# MCXA156 register map
Vendor: nxp.com; File version: 1.0
CPU: CM33 r2p0, little endian, no MPU, FPU, VTOR, 3 interrupt priority bits
Registers are 32-bit, read-write, reset 0x0 unless marked. A register's access mark holds for its fields unless they carry their own. Offsets are from the block's base; [hi:lo] are bit positions; lines under a group give offsets from that group; {n}, {i} and the like mark numbered series; 'fields as' and 'values as' point back to an identical list.

## CAN0 — CAN
Base 0x400CC000
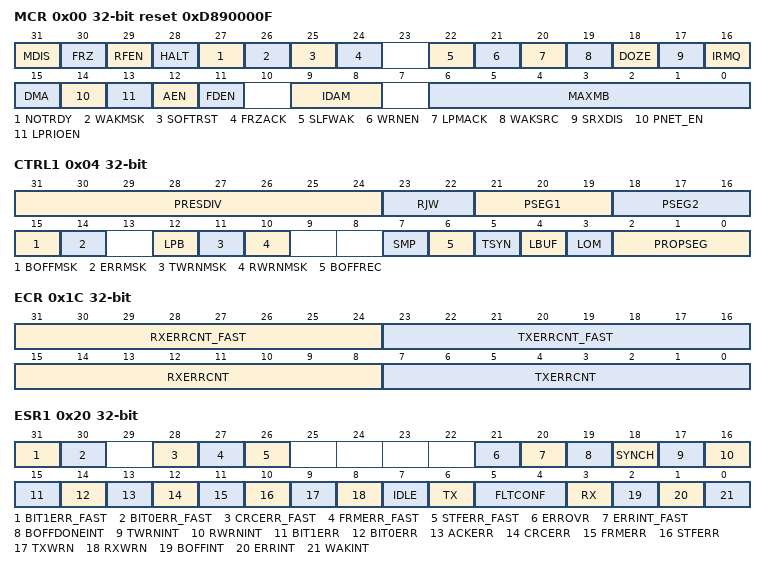
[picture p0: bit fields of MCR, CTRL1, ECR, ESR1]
0x00 MCR reset 0xD890000F — Module Configuration
  [31] MDIS — Module Disable
    0=flexcan_enabled (Enable); 1=flexcan_disabled (Disable)
  [30] FRZ — Freeze Enable
    0=freeze_mode_disabled (Disable); 1=freeze_mode_enabled (Enable)
  [29] RFEN — Legacy RX FIFO Enable
    0=id1 (Disable); 1=id2 (Enable)
  [28] HALT — Halt FlexCAN
    0=HALT_disable (No request); 1=HALT_enable (Enter Freeze mode, if MCR[FRZ] = 1.)
  [27] NOTRDY ro — FlexCAN Not Ready
    0=id1 (FlexCAN is in Normal mode, Listen-Only mode, or Loopback mode.); 1=id2 (FlexCAN is in Disable mode, Doze mode, Stop mode, or Freeze mode.)
  [26] WAKMSK — Wake-up Interrupt Mask
    0=wakeup_interrupt_disabled (Disabled); 1=wakeup_interrupt_enabled (Enabled)
  [25] SOFTRST — Soft Reset
    0=SOFTRST_no_reset_request (No reset); 1=SOFTRST_reset_registers (Soft reset affects reset registers)
  [24] FRZACK ro — Freeze Mode Acknowledge
    0=freeze_mode_no (Not in Freeze mode, prescaler running.); 1=freeze_mode_yes (In Freeze mode, prescaler stopped.)
  [22] SLFWAK — Self Wake-up
    0=self_wakeup_disabled (Disable); 1=self_wakeup_enabled (Enable)
  [21] WRNEN — Warning Interrupt Enable
    0=TWRNINT_RWRNINT_inactive (Disable); 1=TWRNINT_RWRNINT_active (Enable)
  [20] LPMACK ro — Low-Power Mode Acknowledge
    0=low_power_no (Not in a low-power mode); 1=low_power_yes (In a low-power mode)
  [19] WAKSRC — Wake-Up Source
    0=unfiltered_rx_input (No filter applied); 1=filtered_rx_input (Filter applied)
  [18] DOZE — Doze Mode Enable
    0=low_power_doze_disabled (Disable); 1=low_power_doze_enabled (Enable)
  [17] SRXDIS — Self-Reception Disable
    0=self_reception_enabled (Enable); 1=self_reception_disabled (Disable)
  [16] IRMQ — Individual RX Masking and Queue Enable
    0=individual_rx_masking_disabled (Disable); 1=individual_rx_masking_enabled (Enable)
  [15] DMA — DMA Enable
    0=id1 (Disable); 1=id2 (Enable)
  [14] PNET_EN — Pretended Networking Enable
    0=PN_disabled (Disable); 1=PN_enabled (Enable)
  [13] LPRIOEN — Local Priority Enable
    0=local_priority_disabled (Disable); 1=local_priority_enabled (Enable)
  [12] AEN — Abort Enable
    0=abort_disabled (Disabled); 1=abort_enabled (Enabled)
  [11] FDEN — CAN FD Operation Enable
    0=CAN_FD_disabled (Disable); 1=CAN_FD_enabled (Enable)
  [9:8] IDAM — ID Acceptance Mode
    0=one_full_ID (Format A: One full ID (standard and extended) per ID filter table element.); 1=two_full_ID (Format B: Two full standard IDs or two partial 14-bit (standard and extended) IDs per ID filter table element.); 2=four_partial_ID (Format C: Four partial 8-bit standard IDs per ID filter table element.); 3=all_frames_rejected (Format D: All frames rejected.)
  [6:0] MAXMB — Number of the Last Message Buffer
0x04 CTRL1 — Control 1
  [31:24] PRESDIV — Prescaler Division Factor
  [23:22] RJW — Resync Jump Width
  [21:19] PSEG1 — Phase Segment 1
  [18:16] PSEG2 — Phase Segment 2
  [15] BOFFMSK — Bus Off Interrupt Mask
    0=bus_off_int_disabled (Interrupt disabled); 1=bus_off_int_enabled (Interrupt enabled)
  [14] ERRMSK — Error Interrupt Mask
    0=error_int_disabled (Interrupt disabled); 1=error_int_enabled (Interrupt enabled)
  [12] LPB — Loopback Mode
    0=loopback_disabled (Disabled); 1=loopback_enabled (Enabled)
  [11] TWRNMSK — TX Warning Interrupt Mask
    0=tx_warning_int_disabled (Disabled); 1=tx_warning_int_enabled (Enabled)
  [10] RWRNMSK — RX Warning Interrupt Mask
    0=rx_warning_int_disabled (Disabled); 1=rx_warning_int_enabled (Enabled)
  [7] SMP — CAN Bit Sampling
    0=One sample is used to determine the bit value; 1=Three samples are used to determine the value of the received bit: the regular one (sample point) and two preceding samples. A majority rule is used.
  [6] BOFFREC — Bus Off Recovery
    0=auto_recover_enabled (Enabled); 1=auto_recover_disabled (Disabled)
  [5] TSYN — Timer Sync
    0=timer_sync_disabled (Disable); 1=timer_sync_enabled (Enable)
  [4] LBUF — Lowest Buffer Transmitted First
    0=highest_buffer_first (Buffer with highest priority is transmitted first.); 1=lowest_buffer_first (Lowest number buffer is transmitted first.)
  [3] LOM — Listen-Only Mode
    0=listen_only_mode_disabled (Listen-Only mode is deactivated.); 1=listen_only_mode_enabled (FlexCAN module operates in Listen-Only mode.)
  [2:0] PROPSEG — Propagation Segment
0x08 TIMER — Free-Running Timer
  [15:0] TIMER — Timer Value
0x10 RXMGMASK reset not defined — RX Message Buffers Global Mask
  [31:0] MG — Global Mask for RX Message Buffers
0x14 RX14MASK reset not defined — Receive 14 Mask
  [31:0] RX14M — RX Buffer 14 Mask Bits
0x18 RX15MASK reset not defined — Receive 15 Mask
  [31:0] RX15M — RX Buffer 15 Mask Bits
0x1C ECR — Error Counter
  [31:24] RXERRCNT_FAST — Receive Error Counter for Fast Bits
  [23:16] TXERRCNT_FAST — Transmit Error Counter for Fast Bits
  [15:8] RXERRCNT — Receive Error Counter
  [7:0] TXERRCNT — Transmit Error Counter
0x20 ESR1 — Error and Status 1
  [31] BIT1ERR_FAST ro — Fast Bit1 Error Flag
    0=bit1_error_no (No such occurrence.); 1=bit1_error_yes (At least one bit transmitted as recessive is received as dominant.)
  [30] BIT0ERR_FAST ro — Fast Bit0 Error Flag
    0=bit0_error_no (No such occurrence.); 1=bit0_error_yes (At least one bit transmitted as dominant is received as recessive.)
  [28] CRCERR_FAST ro — Fast Cyclic Redundancy Check Error Flag
    0=CRC_error_no (No such occurrence.); 1=CRC_error_yes (A CRC error occurred since last read of this register.)
  [27] FRMERR_FAST ro — Fast Form Error Flag
    0=form_error_no (No such occurrence.); 1=form_error_yes (A form error occurred since last read of this register.)
  [26] STFERR_FAST ro — Fast Stuffing Error Flag
    0=stuffing_error_no (No such occurrence.); 1=stuffing_error_yes (A stuffing error occurred since last read of this register.)
  [21] ERROVR write-1-clears — Error Overrun Flag
    0=overrun_not_occurred (No overrun); 1=overrun_occurred
  [20] ERRINT_FAST write-1-clears — Fast Error Interrupt Flag
    0=errors_data_phase_no (No such occurrence.); 1=errors_data_phase_yes (Error flag set in the data phase of CAN FD frames that have BRS = 1.)
  [19] BOFFDONEINT write-1-clears — Bus Off Done Interrupt Flag
    0=bus_off_not_done (No such occurrence); 1=bus_off_done (FlexCAN module has completed Bus Off process.)
  [18] SYNCH ro — CAN Synchronization Status Flag
    0=CAN_bus_sync_no (Not synchronized); 1=CAN_bus_sync_yes (Synchronized)
  [17] TWRNINT write-1-clears — TX Warning Interrupt Flag
    0=Tx_warning_int_no (No such occurrence); 1=Tx_warning_int_yes (TX error counter changed from less than 96 to greater than or equal to 96.)
  [16] RWRNINT write-1-clears — RX Warning Interrupt Flag
    0=Rx_warning_int_no (No such occurrence); 1=Rx_warning_int_yes (RX error counter changed from less than 96 to greater than or equal to 96.)
  [15] BIT1ERR ro — Bit1 Error Flag
    0=bit1_error_no (No such occurrence.); 1=bit1_error_yes (At least one bit sent as recessive is received as dominant.)
  [14] BIT0ERR ro — Bit0 Error Flag
    0=bit0_error_no (No such occurrence.); 1=bit0_error_yes (At least one bit sent as dominant is received as recessive.)
  [13] ACKERR ro — Acknowledge Error Flag
    0=ACK_error_no (No error); 1=ACK_error_yes (Error occurred since last read of this register.)
  [12] CRCERR ro — Cyclic Redundancy Check Error Flag
    0=CRC_error_no (No error); 1=CRC_error_yes (Error occurred since last read of this register.)
  [11] FRMERR ro — Form Error Flag
    0=form_error_no (No error); 1=form_error_yes (Error occurred since last read of this register.)
  [10] STFERR ro — Stuffing Error Flag
    0=stuffing_error_no (No error); 1=stuffing_error_yes (Error occurred since last read of this register.)
  [9] TXWRN ro — TX Error Warning Flag
    0=TXERRCNT_LT_96 (No such occurrence.); 1=TXERRCNT_GTE_96 (TXERRCNT is 96 or greater.)
  [8] RXWRN ro — RX Error Warning Flag
    0=RXERRCNT_LT_96 (No such occurrence.); 1=RXERRCNT_GTE_96 (RXERRCNT is greater than or equal to 96.)
  [7] IDLE ro
    0=can_bus_not_idle (Not IDLE); 1=can_bus_idle (IDLE)
  [6] TX ro — FlexCAN In Transmission
    0=transmit_message_no (Not transmitting); 1=transmit_message_yes (Transmitting)
  [5:4] FLTCONF ro — Fault Confinement State
    0=error_active; 1=error_passive; 0b1x=bus_off
  [3] RX ro — FlexCAN in Reception Flag
    0=DISABLE (Not receiving); 1=ENABLE (Receiving)
  [2] BOFFINT write-1-clears — Bus Off Interrupt Flag
    0=DISABLE (No such occurrence.); 1=ENABLE (FlexCAN module entered Bus Off state.)
  [1] ERRINT write-1-clears — Error Interrupt Flag
    0=DISABLE (No such occurrence.); 1=ENABLE (Indicates setting of any error flag in the Error and Status register.)
  [0] WAKINT write-1-clears — Wake-up Interrupt Flag
    0=DISABLE (No such occurrence.); 1=ENABLE (Indicates that a recessive-to-dominant transition was received on the CAN bus.)
0x28 IMASK1 — Interrupt Masks 1
  [31:0] BUF31TO0M — Buffer MBi Mask
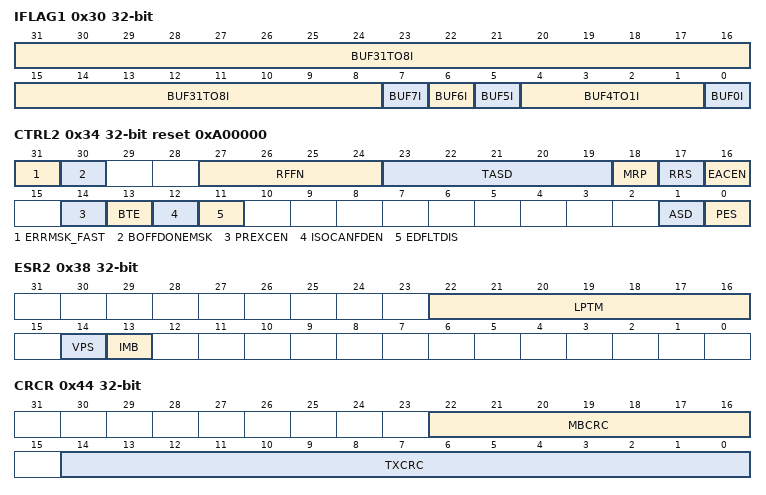
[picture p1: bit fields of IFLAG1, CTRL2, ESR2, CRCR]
0x30 IFLAG1 write-1-clears — Interrupt Flags 1
  [31:8] BUF31TO8I write-1-clears — Buffer MBi Interrupt
  [7] BUF7I write-1-clears — Buffer MB7 Interrupt or Legacy RX FIFO Overflow
    0=id1 (No occurrence of MB7 completing transmission or reception, or no FIFO overflow.); 1=id2 (MB7 completed transmission or reception, or FIFO overflow.)
  [6] BUF6I write-1-clears — Buffer MB6 Interrupt or Legacy RX FIFO Warning
    0=id1 (No occurrence of MB6 completing transmission or reception, or FIFO not almost full.); 1=id2 (MB6 completed transmission or reception, or FIFO almost full.)
  [5] BUF5I write-1-clears — Buffer MB5 Interrupt or Frames available in Legacy RX FIFO
    0=id1 (No occurrence of completed transmission or reception, or no frames available); 1=id2 (MB5 completed transmission or reception, or frames available)
  [4:1] BUF4TO1I write-1-clears — Buffer MBi Interrupt or Reserved
  [0] BUF0I write-1-clears — Buffer MB0 Interrupt or Clear Legacy FIFO bit
    0=buffer_Tx_Rx_not_complete (MB0 has no occurrence of successfully completed transmission or reception.); 1=buffer_Tx_Rx_complete (MB0 has successfully completed transmission or reception.)
0x34 CTRL2 reset 0xA00000 — Control 2
  [31] ERRMSK_FAST — Error Interrupt Mask for Errors Detected in the Data Phase of Fast CAN FD Frames
    0=DISABLE; 1=ENABLE
  [30] BOFFDONEMSK — Bus Off Done Interrupt Mask
    0=DISABLE; 1=ENABLE
  [27:24] RFFN — Number of Legacy Receive FIFO Filters
  [23:19] TASD — Transmission Arbitration Start Delay
  [18] MRP — Message Buffers Reception Priority
    0=id1 (Matching starts from Legacy RX FIFO or Enhanced RX FIFO and continues on message buffers.); 1=id3 (Matching starts from message buffers and continues on Legacy RX FIFO or Enhanced RX FIFO.)
  [17] RRS — Remote Request Storing
    0=remote_response_frame_not_generated (Generated); 1=remote_response_frame_generated (Stored)
  [16] EACEN — Entire Frame Arbitration Field Comparison Enable for RX Message Buffers
    0=RTR_compare_no (Disable); 1=RTR_compare_yes (Enable)
  [14] PREXCEN — Protocol Exception Enable
    0=DISABLE (Disabled); 1=ENABLE (Enabled)
  [13] BTE — Bit Timing Expansion Enable
    0=DISABLE; 1=ENABLE
  [12] ISOCANFDEN — ISO CAN FD Enable
    0=non_ISO (Disable); 1=ISO (Enable)
  [11] EDFLTDIS — Edge Filter Disable
    0=ENABLE (Enabled); 1=DISABLE (Disabled)
  [1] ASD — ACK Suppression Disable
    0=ENABLE (Enabled); 1=DISABLE (Disabled)
  [0] PES — Payload Byte and Bit Order Selection
    0=Big-endian; 1=Little-endian
0x38 ESR2 ro — Error and Status 2
  [22:16] LPTM — Lowest Priority TX Message Buffer
  [14] VPS — Valid Priority Status
    0=invalid; 1=valid
  [13] IMB — Inactive Message Buffer
    0=inactive_mailbox_no (Message buffer indicated by ESR2[LPTM] is not inactive.); 1=inactive_mailbox_yes (At least one message buffer is inactive.)
0x44 CRCR ro — Cyclic Redundancy Check
  [22:16] MBCRC — CRC Message Buffer
  [14:0] TXCRC — Transmitted CRC value
0x48 RXFGMASK reset not defined — Legacy RX FIFO Global Mask
  [31:0] FGM — Legacy RX FIFO Global Mask Bits
0x4C RXFIR ro reset not defined — Legacy RX FIFO Information
  [8:0] IDHIT — Identifier Acceptance Filter Hit Indicator
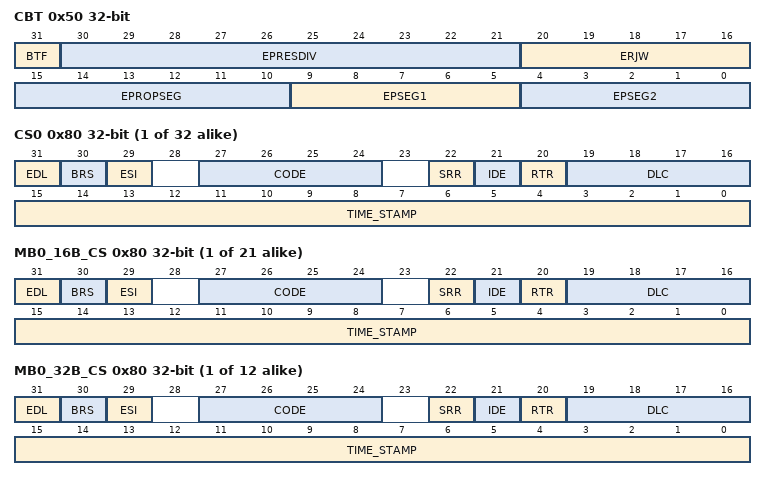
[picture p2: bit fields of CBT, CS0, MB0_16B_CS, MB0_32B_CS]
0x50 CBT — CAN Bit Timing
  [31] BTF — Bit Timing Format Enable
    0=DISABLE; 1=ENABLE
  [30:21] EPRESDIV — Extended Prescaler Division Factor
  [20:16] ERJW — Extended Resync Jump Width
  [15:10] EPROPSEG — Extended Propagation Segment
  [9:5] EPSEG1 — Extended Phase Segment 1
  [4:0] EPSEG2 — Extended Phase Segment 2
{0x80+0x10*i} CS{i} (MB_SIZE view) (i=0..31) — Message Buffer {i} CS Register
  [31] EDL — Extended Data Length. This bit distinguishes between CAN format and CAN FD format frames. The EDL bit must not be set for Message Buffers configured to RANSWER with code field 0b1010.
  [30] BRS — Bit Rate Switch. This bit defines whether the bit rate is switched inside a CAN FD format frame.
  [29] ESI — Error State Indicator. This bit indicates if the transmitting node is error active or error passive.
  [27:24] CODE — Message Buffer Code. This 4-bit field can be accessed (read or write) by the CPU and by the FlexCAN module itself, as part of the message buffer matching and arbitration process.
  [22] SRR — Substitute Remote Request. Contains a fixed recessive bit.
  [21] IDE — ID Extended. One/zero for extended/standard format frame.
  [20] RTR — Remote Transmission Request. One/zero for remote/data frame.
  [19:16] DLC — Length of the data to be stored/transmitted.
  [15:0] TIME_STAMP — Free-Running Counter Time stamp. This 16-bit field is a copy of the Free-Running Timer, captured for Tx and Rx frames at the time when the beginning of the Identifier field appears on the CAN bus.
{0x80+0x18*i} MB{i}_16B_CS (MB_SIZE view) (i=0..20) — Message Buffer {i} CS Register
  fields as CS0
{0x80+0x28*i} MB{i}_32B_CS (MB_SIZE view) (i=0..11) — Message Buffer {i} CS Register
  fields as CS0
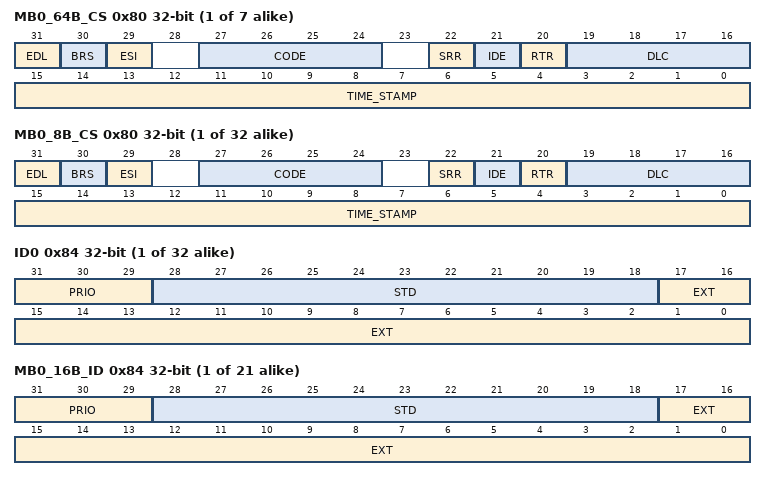
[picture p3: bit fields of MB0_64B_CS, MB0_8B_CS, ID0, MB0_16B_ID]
{0x80+0x48*i} MB{i}_64B_CS (MB_SIZE view) (i=0..6) — Message Buffer {i} CS Register
  fields as CS0
{0x80+0x10*i} MB{i}_8B_CS (MB_SIZE view) (i=0..31) — Message Buffer {i} CS Register
  fields as CS0
{0x84+0x10*i} ID{i} (MB_SIZE view) (i=0..31) — Message Buffer {i} ID Register
  [31:29] PRIO — Local priority. This 3-bit fieldis only used when LPRIO_EN bit is set in MCR and it only makes sense for Tx buffers. These bits are not transmitted. They are appended to the regular ID to define the transmission priority.
  [28:18] STD — Contains standard/extended (HIGH word) identifier of message buffer.
  [17:0] EXT — Contains extended (LOW word) identifier of message buffer.
{0x84+0x18*i} MB{i}_16B_ID (MB_SIZE view) (i=0..20) — Message Buffer {i} ID Register
  fields as ID0
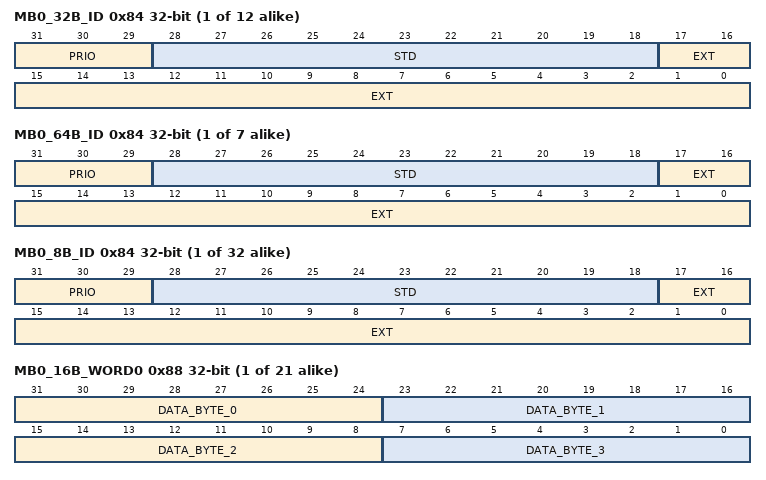
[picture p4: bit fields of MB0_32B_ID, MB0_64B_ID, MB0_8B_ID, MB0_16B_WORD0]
{0x84+0x28*i} MB{i}_32B_ID (MB_SIZE view) (i=0..11) — Message Buffer {i} ID Register
  fields as ID0
{0x84+0x48*i} MB{i}_64B_ID (MB_SIZE view) (i=0..6) — Message Buffer {i} ID Register
  fields as ID0
{0x84+0x10*i} MB{i}_8B_ID (MB_SIZE view) (i=0..31) — Message Buffer {i} ID Register
  fields as ID0
{0x88+0x18*i} MB{i}_16B_WORD0 (MB_SIZE view) (i=0..20) — Message Buffer {i} WORD_16B Register
  [31:24] DATA_BYTE_0 — Data byte 3 of Rx/Tx frame.
  [23:16] DATA_BYTE_1 — Data byte 2 of Rx/Tx frame.
  [15:8] DATA_BYTE_2 — Data byte 1 of Rx/Tx frame.
  [7:0] DATA_BYTE_3 — Data byte 0 of Rx/Tx frame.
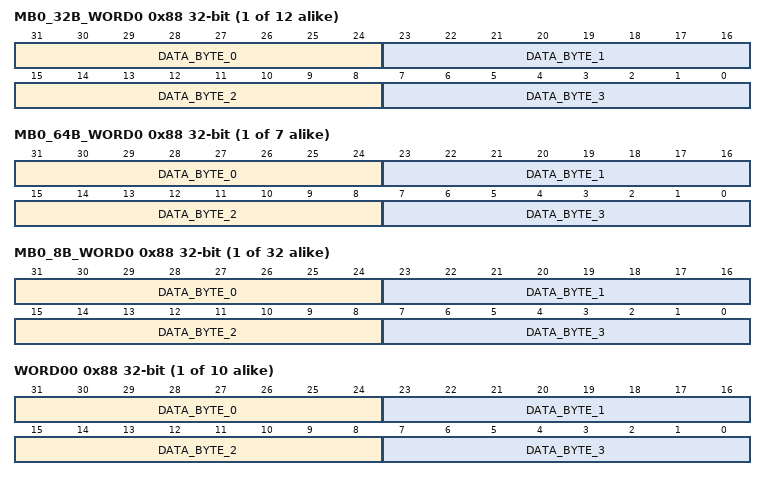
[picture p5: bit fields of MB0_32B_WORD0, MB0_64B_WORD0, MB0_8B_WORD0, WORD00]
{0x88+0x28*i} MB{i}_32B_WORD0 (MB_SIZE view) (i=0..11) — Message Buffer {i} WORD_32B Register
  fields as MB0_16B_WORD0
{0x88+0x48*i} MB{i}_64B_WORD0 (MB_SIZE view) (i=0..6) — Message Buffer {i} WORD_64B Register
  fields as MB0_16B_WORD0
{0x88+0x10*i} MB{i}_8B_WORD0 (MB_SIZE view) (i=0..31) — Message Buffer {i} WORD_8B Register
  fields as MB0_16B_WORD0
{0x88+0x10*i} WORD{i:02} (MB_SIZE view) (i=0..9) — Message Buffer {i} WORD0 Register
  fields as MB0_16B_WORD0
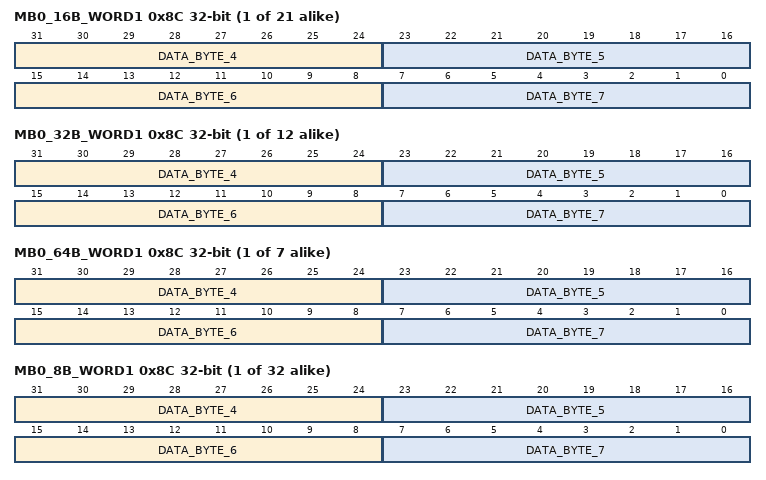
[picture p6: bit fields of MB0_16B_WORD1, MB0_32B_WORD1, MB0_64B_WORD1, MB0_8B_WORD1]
{0x8C+0x18*i} MB{i}_16B_WORD1 (MB_SIZE view) (i=0..20) — Message Buffer {i} WORD_16B Register
  [31:24] DATA_BYTE_4 — Data byte 3 of Rx/Tx frame.
  [23:16] DATA_BYTE_5 — Data byte 2 of Rx/Tx frame.
  [15:8] DATA_BYTE_6 — Data byte 1 of Rx/Tx frame.
  [7:0] DATA_BYTE_7 — Data byte 0 of Rx/Tx frame.
{0x8C+0x28*i} MB{i}_32B_WORD1 (MB_SIZE view) (i=0..11) — Message Buffer {i} WORD_32B Register
  fields as MB0_16B_WORD1
{0x8C+0x48*i} MB{i}_64B_WORD1 (MB_SIZE view) (i=0..6) — Message Buffer {i} WORD_64B Register
  fields as MB0_16B_WORD1
{0x8C+0x10*i} MB{i}_8B_WORD1 (MB_SIZE view) (i=0..31) — Message Buffer {i} WORD_8B Register
  fields as MB0_16B_WORD1
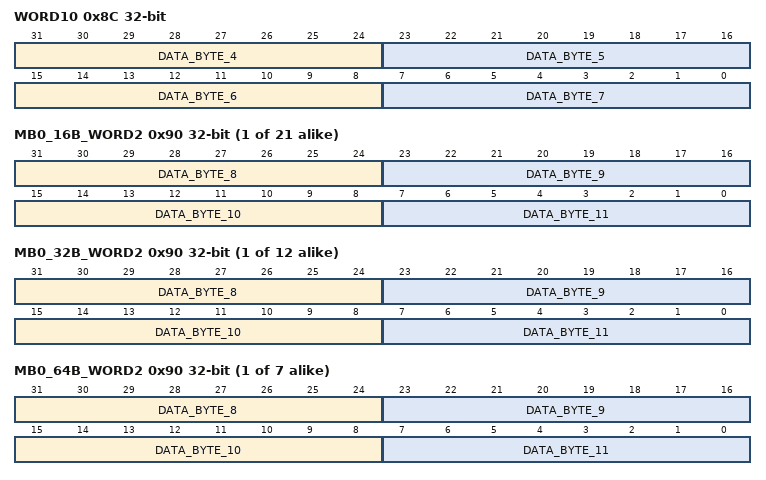
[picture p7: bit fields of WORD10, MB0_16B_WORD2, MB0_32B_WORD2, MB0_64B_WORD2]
0x8C WORD10 (MB_SIZE view) — Message Buffer 0 WORD1 Register
  fields as MB0_16B_WORD1
{0x90+0x18*i} MB{i}_16B_WORD2 (MB_SIZE view) (i=0..20) — Message Buffer {i} WORD_16B Register
  [31:24] DATA_BYTE_8 — Data byte 3 of Rx/Tx frame.
  [23:16] DATA_BYTE_9 — Data byte 2 of Rx/Tx frame.
  [15:8] DATA_BYTE_10 — Data byte 1 of Rx/Tx frame.
  [7:0] DATA_BYTE_11 — Data byte 0 of Rx/Tx frame.
{0x90+0x28*i} MB{i}_32B_WORD2 (MB_SIZE view) (i=0..11) — Message Buffer {i} WORD_32B Register
  fields as MB0_16B_WORD2
{0x90+0x48*i} MB{i}_64B_WORD2 (MB_SIZE view) (i=0..6) — Message Buffer {i} WORD_64B Register
  fields as MB0_16B_WORD2
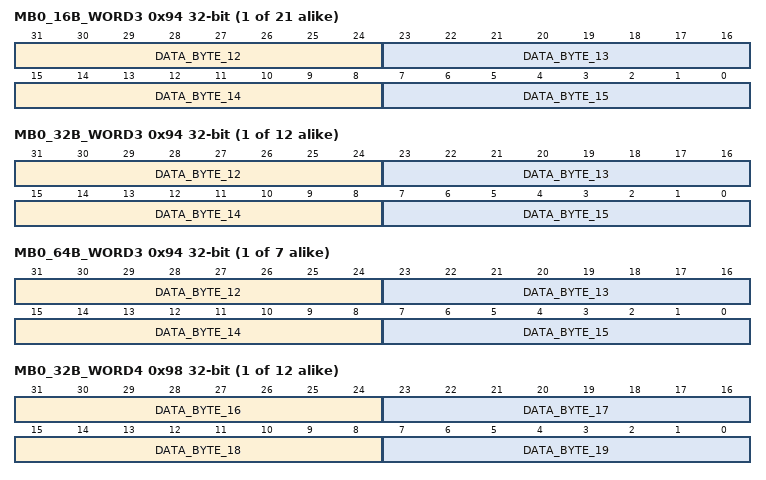
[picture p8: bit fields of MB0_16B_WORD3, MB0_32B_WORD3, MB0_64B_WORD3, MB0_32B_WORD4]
{0x94+0x18*i} MB{i}_16B_WORD3 (MB_SIZE view) (i=0..20) — Message Buffer {i} WORD_16B Register
  [31:24] DATA_BYTE_12 — Data byte 3 of Rx/Tx frame.
  [23:16] DATA_BYTE_13 — Data byte 2 of Rx/Tx frame.
  [15:8] DATA_BYTE_14 — Data byte 1 of Rx/Tx frame.
  [7:0] DATA_BYTE_15 — Data byte 0 of Rx/Tx frame.
{0x94+0x28*i} MB{i}_32B_WORD3 (MB_SIZE view) (i=0..11) — Message Buffer {i} WORD_32B Register
  fields as MB0_16B_WORD3
{0x94+0x48*i} MB{i}_64B_WORD3 (MB_SIZE view) (i=0..6) — Message Buffer {i} WORD_64B Register
  fields as MB0_16B_WORD3
{0x98+0x28*i} MB{i}_32B_WORD4 (MB_SIZE view) (i=0..11) — Message Buffer {i} WORD_32B Register
  [31:24] DATA_BYTE_16 — Data byte 3 of Rx/Tx frame.
  [23:16] DATA_BYTE_17 — Data byte 2 of Rx/Tx frame.
  [15:8] DATA_BYTE_18 — Data byte 1 of Rx/Tx frame.
  [7:0] DATA_BYTE_19 — Data byte 0 of Rx/Tx frame.
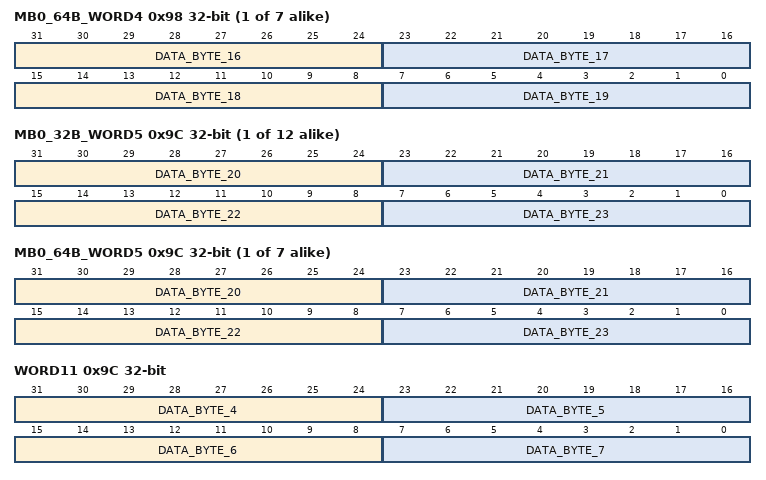
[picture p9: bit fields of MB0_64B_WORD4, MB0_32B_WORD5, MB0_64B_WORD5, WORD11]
{0x98+0x48*i} MB{i}_64B_WORD4 (MB_SIZE view) (i=0..6) — Message Buffer {i} WORD_64B Register
  fields as MB0_32B_WORD4
{0x9C+0x28*i} MB{i}_32B_WORD5 (MB_SIZE view) (i=0..11) — Message Buffer {i} WORD_32B Register
  [31:24] DATA_BYTE_20 — Data byte 3 of Rx/Tx frame.
  [23:16] DATA_BYTE_21 — Data byte 2 of Rx/Tx frame.
  [15:8] DATA_BYTE_22 — Data byte 1 of Rx/Tx frame.
  [7:0] DATA_BYTE_23 — Data byte 0 of Rx/Tx frame.
{0x9C+0x48*i} MB{i}_64B_WORD5 (MB_SIZE view) (i=0..6) — Message Buffer {i} WORD_64B Register
  fields as MB0_32B_WORD5
0x9C WORD11 (MB_SIZE view) — Message Buffer 1 WORD1 Register
  fields as MB0_16B_WORD1
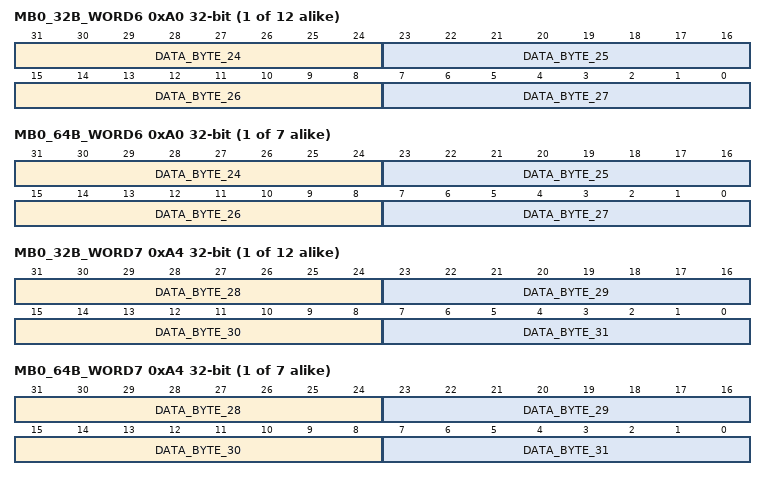
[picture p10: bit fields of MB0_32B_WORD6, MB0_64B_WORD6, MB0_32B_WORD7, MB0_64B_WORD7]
{0xA0+0x28*i} MB{i}_32B_WORD6 (MB_SIZE view) (i=0..11) — Message Buffer {i} WORD_32B Register
  [31:24] DATA_BYTE_24 — Data byte 3 of Rx/Tx frame.
  [23:16] DATA_BYTE_25 — Data byte 2 of Rx/Tx frame.
  [15:8] DATA_BYTE_26 — Data byte 1 of Rx/Tx frame.
  [7:0] DATA_BYTE_27 — Data byte 0 of Rx/Tx frame.
{0xA0+0x48*i} MB{i}_64B_WORD6 (MB_SIZE view) (i=0..6) — Message Buffer {i} WORD_64B Register
  fields as MB0_32B_WORD6
{0xA4+0x28*i} MB{i}_32B_WORD7 (MB_SIZE view) (i=0..11) — Message Buffer {i} WORD_32B Register
  [31:24] DATA_BYTE_28 — Data byte 3 of Rx/Tx frame.
  [23:16] DATA_BYTE_29 — Data byte 2 of Rx/Tx frame.
  [15:8] DATA_BYTE_30 — Data byte 1 of Rx/Tx frame.
  [7:0] DATA_BYTE_31 — Data byte 0 of Rx/Tx frame.
{0xA4+0x48*i} MB{i}_64B_WORD7 (MB_SIZE view) (i=0..6) — Message Buffer {i} WORD_64B Register
  fields as MB0_32B_WORD7
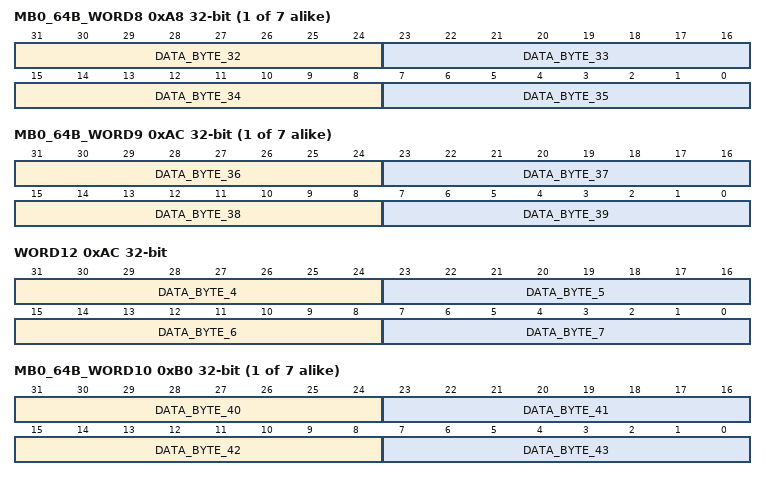
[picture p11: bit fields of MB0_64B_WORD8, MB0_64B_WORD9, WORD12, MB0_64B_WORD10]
{0xA8+0x48*i} MB{i}_64B_WORD8 (MB_SIZE view) (i=0..6) — Message Buffer {i} WORD_64B Register
  [31:24] DATA_BYTE_32 — Data byte 3 of Rx/Tx frame.
  [23:16] DATA_BYTE_33 — Data byte 2 of Rx/Tx frame.
  [15:8] DATA_BYTE_34 — Data byte 1 of Rx/Tx frame.
  [7:0] DATA_BYTE_35 — Data byte 0 of Rx/Tx frame.
{0xAC+0x48*i} MB{i}_64B_WORD9 (MB_SIZE view) (i=0..6) — Message Buffer {i} WORD_64B Register
  [31:24] DATA_BYTE_36 — Data byte 3 of Rx/Tx frame.
  [23:16] DATA_BYTE_37 — Data byte 2 of Rx/Tx frame.
  [15:8] DATA_BYTE_38 — Data byte 1 of Rx/Tx frame.
  [7:0] DATA_BYTE_39 — Data byte 0 of Rx/Tx frame.
0xAC WORD12 (MB_SIZE view) — Message Buffer 2 WORD1 Register
  fields as MB0_16B_WORD1
{0xB0+0x48*i} MB{i}_64B_WORD10 (MB_SIZE view) (i=0..6) — Message Buffer {i} WORD_64B Register
  [31:24] DATA_BYTE_40 — Data byte 3 of Rx/Tx frame.
  [23:16] DATA_BYTE_41 — Data byte 2 of Rx/Tx frame.
  [15:8] DATA_BYTE_42 — Data byte 1 of Rx/Tx frame.
  [7:0] DATA_BYTE_43 — Data byte 0 of Rx/Tx frame.
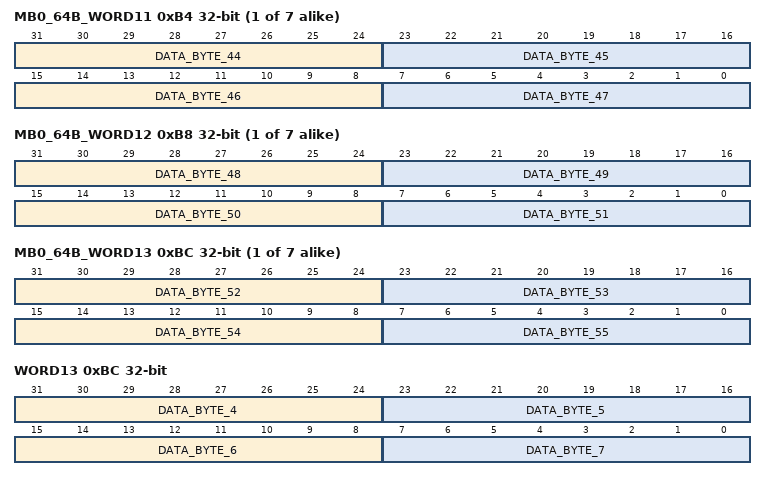
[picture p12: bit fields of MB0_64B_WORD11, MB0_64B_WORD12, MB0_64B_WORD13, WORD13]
{0xB4+0x48*i} MB{i}_64B_WORD11 (MB_SIZE view) (i=0..6) — Message Buffer {i} WORD_64B Register
  [31:24] DATA_BYTE_44 — Data byte 3 of Rx/Tx frame.
  [23:16] DATA_BYTE_45 — Data byte 2 of Rx/Tx frame.
  [15:8] DATA_BYTE_46 — Data byte 1 of Rx/Tx frame.
  [7:0] DATA_BYTE_47 — Data byte 0 of Rx/Tx frame.
{0xB8+0x48*i} MB{i}_64B_WORD12 (MB_SIZE view) (i=0..6) — Message Buffer {i} WORD_64B Register
  [31:24] DATA_BYTE_48 — Data byte 3 of Rx/Tx frame.
  [23:16] DATA_BYTE_49 — Data byte 2 of Rx/Tx frame.
  [15:8] DATA_BYTE_50 — Data byte 1 of Rx/Tx frame.
  [7:0] DATA_BYTE_51 — Data byte 0 of Rx/Tx frame.
{0xBC+0x48*i} MB{i}_64B_WORD13 (MB_SIZE view) (i=0..6) — Message Buffer {i} WORD_64B Register
  [31:24] DATA_BYTE_52 — Data byte 3 of Rx/Tx frame.
  [23:16] DATA_BYTE_53 — Data byte 2 of Rx/Tx frame.
  [15:8] DATA_BYTE_54 — Data byte 1 of Rx/Tx frame.
  [7:0] DATA_BYTE_55 — Data byte 0 of Rx/Tx frame.
0xBC WORD13 (MB_SIZE view) — Message Buffer 3 WORD1 Register
  fields as MB0_16B_WORD1
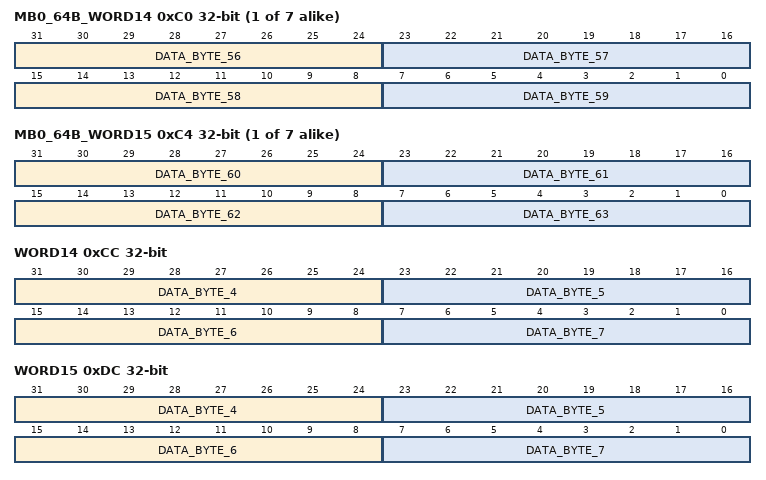
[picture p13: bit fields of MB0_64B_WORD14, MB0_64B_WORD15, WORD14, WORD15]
{0xC0+0x48*i} MB{i}_64B_WORD14 (MB_SIZE view) (i=0..6) — Message Buffer {i} WORD_64B Register
  [31:24] DATA_BYTE_56 — Data byte 3 of Rx/Tx frame.
  [23:16] DATA_BYTE_57 — Data byte 2 of Rx/Tx frame.
  [15:8] DATA_BYTE_58 — Data byte 1 of Rx/Tx frame.
  [7:0] DATA_BYTE_59 — Data byte 0 of Rx/Tx frame.
{0xC4+0x48*i} MB{i}_64B_WORD15 (MB_SIZE view) (i=0..6) — Message Buffer {i} WORD_64B Register
  [31:24] DATA_BYTE_60 — Data byte 3 of Rx/Tx frame.
  [23:16] DATA_BYTE_61 — Data byte 2 of Rx/Tx frame.
  [15:8] DATA_BYTE_62 — Data byte 1 of Rx/Tx frame.
  [7:0] DATA_BYTE_63 — Data byte 0 of Rx/Tx frame.
0xCC WORD14 (MB_SIZE view) — Message Buffer 4 WORD1 Register
  fields as MB0_16B_WORD1
0xDC WORD15 (MB_SIZE view) — Message Buffer 5 WORD1 Register
  fields as MB0_16B_WORD1
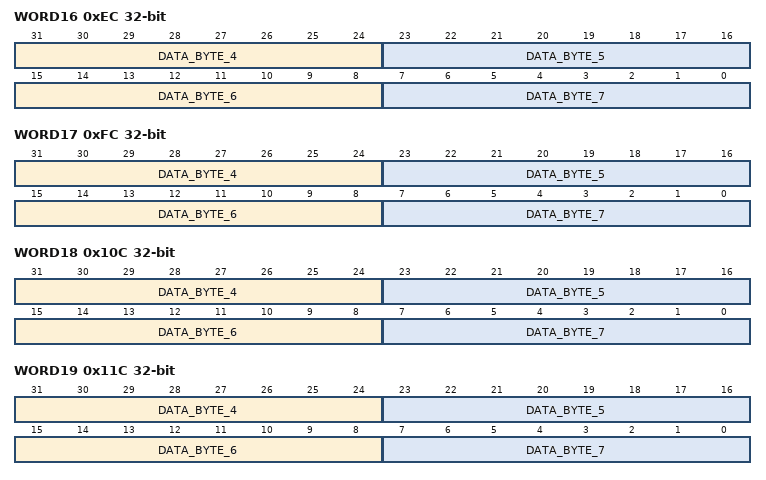
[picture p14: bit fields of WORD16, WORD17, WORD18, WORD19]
0xEC WORD16 (MB_SIZE view) — Message Buffer 6 WORD1 Register
  fields as MB0_16B_WORD1
0xFC WORD17 (MB_SIZE view) — Message Buffer 7 WORD1 Register
  fields as MB0_16B_WORD1
0x10C WORD18 (MB_SIZE view) — Message Buffer 8 WORD1 Register
  fields as MB0_16B_WORD1
0x11C WORD19 (MB_SIZE view) — Message Buffer 9 WORD1 Register
  fields as MB0_16B_WORD1
0x128 WORD010 (MB_SIZE view) — Message Buffer 10 WORD0 Register
  fields as MB0_16B_WORD0
0x12C WORD110 (MB_SIZE view) — Message Buffer 10 WORD1 Register
  fields as MB0_16B_WORD1
0x138 WORD011 (MB_SIZE view) — Message Buffer 11 WORD0 Register
  fields as MB0_16B_WORD0
0x13C WORD111 (MB_SIZE view) — Message Buffer 11 WORD1 Register
  fields as MB0_16B_WORD1
0x148 WORD012 (MB_SIZE view) — Message Buffer 12 WORD0 Register
  fields as MB0_16B_WORD0
0x14C WORD112 (MB_SIZE view) — Message Buffer 12 WORD1 Register
  fields as MB0_16B_WORD1
0x158 WORD013 (MB_SIZE view) — Message Buffer 13 WORD0 Register
  fields as MB0_16B_WORD0
0x15C WORD113 (MB_SIZE view) — Message Buffer 13 WORD1 Register
  fields as MB0_16B_WORD1
0x168 WORD014 (MB_SIZE view) — Message Buffer 14 WORD0 Register
  fields as MB0_16B_WORD0
0x16C WORD114 (MB_SIZE view) — Message Buffer 14 WORD1 Register
  fields as MB0_16B_WORD1
0x178 WORD015 (MB_SIZE view) — Message Buffer 15 WORD0 Register
  fields as MB0_16B_WORD0
0x17C WORD115 (MB_SIZE view) — Message Buffer 15 WORD1 Register
  fields as MB0_16B_WORD1
0x188 WORD016 (MB_SIZE view) — Message Buffer 16 WORD0 Register
  fields as MB0_16B_WORD0
0x18C WORD116 (MB_SIZE view) — Message Buffer 16 WORD1 Register
  fields as MB0_16B_WORD1
0x198 WORD017 (MB_SIZE view) — Message Buffer 17 WORD0 Register
  fields as MB0_16B_WORD0
0x19C WORD117 (MB_SIZE view) — Message Buffer 17 WORD1 Register
  fields as MB0_16B_WORD1
0x1A8 WORD018 (MB_SIZE view) — Message Buffer 18 WORD0 Register
  fields as MB0_16B_WORD0
0x1AC WORD118 (MB_SIZE view) — Message Buffer 18 WORD1 Register
  fields as MB0_16B_WORD1
{0x88+0x10*i} WORD{i:03} (MB_SIZE view) (i=19..31) — Message Buffer {i} WORD0 Register
  fields as MB0_16B_WORD0
0x1BC WORD119 (MB_SIZE view) — Message Buffer 19 WORD1 Register
  fields as MB0_16B_WORD1
0x1CC WORD120 (MB_SIZE view) — Message Buffer 20 WORD1 Register
  fields as MB0_16B_WORD1
0x1DC WORD121 (MB_SIZE view) — Message Buffer 21 WORD1 Register
  fields as MB0_16B_WORD1
0x1EC WORD122 (MB_SIZE view) — Message Buffer 22 WORD1 Register
  fields as MB0_16B_WORD1
0x1FC WORD123 (MB_SIZE view) — Message Buffer 23 WORD1 Register
  fields as MB0_16B_WORD1
0x20C WORD124 (MB_SIZE view) — Message Buffer 24 WORD1 Register
  fields as MB0_16B_WORD1
0x21C WORD125 (MB_SIZE view) — Message Buffer 25 WORD1 Register
  fields as MB0_16B_WORD1
0x22C WORD126 (MB_SIZE view) — Message Buffer 26 WORD1 Register
  fields as MB0_16B_WORD1
0x23C WORD127 (MB_SIZE view) — Message Buffer 27 WORD1 Register
  fields as MB0_16B_WORD1
0x24C WORD128 (MB_SIZE view) — Message Buffer 28 WORD1 Register
  fields as MB0_16B_WORD1
0x25C WORD129 (MB_SIZE view) — Message Buffer 29 WORD1 Register
  fields as MB0_16B_WORD1
0x26C WORD130 (MB_SIZE view) — Message Buffer 30 WORD1 Register
  fields as MB0_16B_WORD1
0x27C WORD131 (MB_SIZE view) — Message Buffer 31 WORD1 Register
  fields as MB0_16B_WORD1
{0x880+4i} RXIMR[{i}] (i=0..31) reset not defined — Receive Individual Mask
  [31:0] MI — Individual Mask Bits
0xB00 CTRL1_PN reset 0x100 — Pretended Networking Control 1
  [17] WTOF_MSK — Wake-up by Timeout Flag Mask
    0=DISABLE; 1=ENABLE
  [16] WUMF_MSK — Wake-up by Matching Flag Mask
    0=DISABLE; 1=ENABLE
  [15:8] NMATCH — Number of Messages Matching the Same Filtering Criteria
    1=match_1 (Once); 2=match_2 (Twice); 255=match_255 (255 times)
  [5:4] PLFS — Payload Filtering Selection
    0=match_exact (Match payload contents to an exact target value); 1=match_GTE (Match a payload value greater than or equal to a specified target value); 2=match_LTE (Match a payload value smaller than or equal to a specified target value); 3=match_range (Match upon a payload value within a range of values, inclusive)
  [3:2] IDFS — ID Filtering Selection
    0=match_exact (Match ID contents to an exact target value); 1=match_GTE (Match an ID value greater than or equal to a specified target value); 2=match_LTE (Match an ID value smaller than or equal to a specified target value); 3=match_range (Match an ID value within a range of values, inclusive)
  [1:0] FCS — Filtering Combination Selection
    0=ID_filtering (Message ID filtering only); 1=ID_payload_filtering (Message ID filtering and payload filtering); 2=ID_filtering_number (Message ID filtering occurring a specified number of times); 3=ID_payload_filtering_number (Message ID filtering and payload filtering a specified number of times)
0xB04 CTRL2_PN — Pretended Networking Control 2
  [15:0] MATCHTO — Timeout for No Message Matching the Filtering Criteria
0xB08 WU_MTC — Pretended Networking Wake-Up Match
  [17] WTOF write-1-clears — Wake-up by Timeout Flag Bit
    0=no_wakeup (No event detected); 1=wakeup (Event detected)
  [16] WUMF write-1-clears — Wake-up by Match Flag
    0=no_match (No event detected); 1=match (Event detected)
  [15:8] MCOUNTER ro — Number of Matches in Pretended Networking
0xB0C FLT_ID1 — Pretended Networking ID Filter 1
  [30] FLT_IDE — ID Extended Filter
    0=standard; 1=extended
  [29] FLT_RTR — Remote Transmission Request Filter
    0=Reject remote frame (accept data frame); 1=Accept remote frame
  [28:0] FLT_ID1 — ID Filter 1 for Pretended Networking filtering
0xB10 FLT_DLC reset 0x8 — Pretended Networking Data Length Code (DLC) Filter
  [19:16] FLT_DLC_LO — Lower Limit for Length of Data Bytes Filter
  [3:0] FLT_DLC_HI — Upper Limit for Length of Data Bytes Filter
0xB14 PL1_LO — Pretended Networking Payload Low Filter 1
  [31-8n:24-8n] Data_byte_{n} (n=0..3)
0xB18 PL1_HI — Pretended Networking Payload High Filter 1
  [63-8n:56-8n] Data_byte_{n} (n=4..7)
0xB1C FLT_ID2_IDMASK — Pretended Networking ID Filter 2 or ID Mask
  [30] IDE_MSK — ID Extended Mask
    0=frame_format_no (The corresponding bit in the filter is "don't care."); 1=frame_format_yes (The corresponding bit in the filter is checked.)
  [29] RTR_MSK — Remote Transmission Request Mask
    0=frame_type_no (The corresponding bit in the filter is "don't care."); 1=frame_type_yes (The corresponding bit in the filter is checked.)
  [28:0] FLT_ID2_IDMASK — ID Filter 2 for Pretended Networking Filtering or ID Mask Bits for Pretended Networking ID Filtering
0xB20 PL2_PLMASK_LO — Pretended Networking Payload Low Filter 2 and Payload Low Mask
  [31-8n:24-8n] Data_byte_{n} (n=0..3)
0xB24 PL2_PLMASK_HI — Pretended Networking Payload High Filter 2 and Payload High Mask
  [63-8n:56-8n] Data_byte_{n} (n=4..7)
{0xB40+0x10*i} WMB[{i}] (i=0..3) group
  0x00 WMB_CS ro — Wake-Up Message Buffer
    [22] SRR — Substitute Remote Request
      0=dominant; 1=recessive
    [21] IDE — ID Extended Bit
      0=standard; 1=extended
    [20] RTR — Remote Transmission Request
      0=not_remote (Data); 1=remote
    [19:16] DLC — Length of Data in Bytes
  0x04 WMB_ID ro — Wake-Up Message Buffer for ID
    [28:0] ID — Received ID in Pretended Networking Mode
  0x08 WMB_D03 ro — Wake-Up Message Buffer for Data 0-3
    [31-8n:24-8n] Data_byte_{n} (n=0..3)
  0x0C WMB_D47 ro — Wake-Up Message Buffer Register Data 4-7
    [63-8n:56-8n] Data_byte_{n} (n=4..7)
0xBF0 EPRS — Enhanced CAN Bit Timing Prescalers
  [25:16] EDPRESDIV — Extended Data Phase Prescaler Division Factor
  [9:0] ENPRESDIV — Extended Nominal Prescaler Division Factor
0xBF4 ENCBT — Enhanced Nominal CAN Bit Timing
  [28:22] NRJW — Nominal Resynchronization Jump Width
  [18:12] NTSEG2 — Nominal Time Segment 2
  [7:0] NTSEG1 — Nominal Time Segment 1
0xBF8 EDCBT — Enhanced Data Phase CAN Bit Timing
  [25:22] DRJW — Data Phase Resynchronization Jump Width
  [15:12] DTSEG2 — Data Phase Time Segment 2
  [4:0] DTSEG1 — Data Phase Segment 1
0xBFC ETDC — Enhanced Transceiver Delay Compensation
  [31] ETDCEN — Transceiver Delay Compensation Enable
    0=DISABLE; 1=ENABLE
  [30] TDMDIS — Transceiver Delay Measurement Disable
    0=ENABLE; 1=DISABLE
  [22:16] ETDCOFF — Enhanced Transceiver Delay Compensation Offset
  [15] ETDCFAIL write-1-clears — Transceiver Delay Compensation Fail
    0=in_range; 1=out_of_range
  [7:0] ETDCVAL ro — Enhanced Transceiver Delay Compensation Value
0xC00 FDCTRL reset 0x80000100 — CAN FD Control
  [31] FDRATE — Bit Rate Switch Enable
    0=nominal (Disable); 1=bit_rate_switching (Enable)
  [17:16] MBDSR0 — Message Buffer Data Size for Region 0
    0=R0_8_bytes (8 bytes); 1=R0_16_bytes (16 bytes); 2=R0_32_bytes (32 bytes); 3=R0_64_bytes (64 bytes)
  [15] TDCEN — Transceiver Delay Compensation Enable
    0=DISABLE; 1=ENABLE
  [14] TDCFAIL write-1-clears — Transceiver Delay Compensation Fail
    0=in_range; 1=out_of_range
  [12:8] TDCOFF — Transceiver Delay Compensation Offset
  [5:0] TDCVAL ro — Transceiver Delay Compensation Value
0xC04 FDCBT — CAN FD Bit Timing
  [29:20] FPRESDIV — Fast Prescaler Division Factor
  [18:16] FRJW — Fast Resync Jump Width
  [14:10] FPROPSEG — Fast Propagation Segment
  [7:5] FPSEG1 — Fast Phase Segment 1
  [2:0] FPSEG2 — Fast Phase Segment 2
0xC08 FDCRC ro — CAN FD CRC
  [30:24] FD_MBCRC — CRC Message Buffer Number for FD_TXCRC
  [20:0] FD_TXCRC — Extended Transmitted CRC value
0xC0C ERFCR — Enhanced RX FIFO Control
  [31] ERFEN — Enhanced RX FIFO enable
    0=DISABLE; 1=ENABLE
  [30:26] DMALW — DMA Last Word
  [22:16] NEXIF — Number of Extended ID Filter Elements
  [13:8] NFE — Number of Enhanced RX FIFO Filter Elements
  [4:0] ERFWM — Enhanced RX FIFO Watermark
0xC10 ERFIER — Enhanced RX FIFO Interrupt Enable
  [all] fields
    0=DISABLE; 1=ENABLE
  [31] ERFUFWIE — Enhanced RX FIFO Underflow Interrupt Enable
  [30] ERFOVFIE — Enhanced RX FIFO Overflow Interrupt Enable
  [29] ERFWMIIE — Enhanced RX FIFO Watermark Indication Interrupt Enable
  [28] ERFDAIE — Enhanced RX FIFO Data Available Interrupt Enable
0xC14 ERFSR — Enhanced RX FIFO Status
  [31] ERFUFW write-1-clears — Enhanced RX FIFO Underflow Flag
    0=no_underflow (No such occurrence); 1=underflow
  [30] ERFOVF write-1-clears — Enhanced RX FIFO Overflow Flag
    0=no_overflow (No such occurrence); 1=overflow
  [29] ERFWMI write-1-clears — Enhanced RX FIFO Watermark Indication Flag
    0=watermark_no (No such occurrence); 1=watermark_yes (Number of messages in FIFO is greater than the watermark)
  [28] ERFDA write-1-clears — Enhanced RX FIFO Data Available Flag
    0=no_message_stored (No such occurrence); 1=message_stored (At least one message stored in Enhanced RX FIFO)
  [27] ERFCLR — Enhanced RX FIFO Clear
    0=no_effect; 1=Clear enhanced RX FIFO content
  [17] ERFE ro — Enhanced RX FIFO Empty Flag
    0=not_empty; 1=empty
  [16] ERFF ro — Enhanced RX FIFO Full Flag
    0=not_full; 1=full
  [5:0] ERFEL ro — Enhanced RX FIFO Elements
{0x3000+4i} ERFFEL[{i}] (i=0..31) reset not defined — Enhanced RX FIFO Filter Element
  [31:0] FEL — Filter Element Bits
